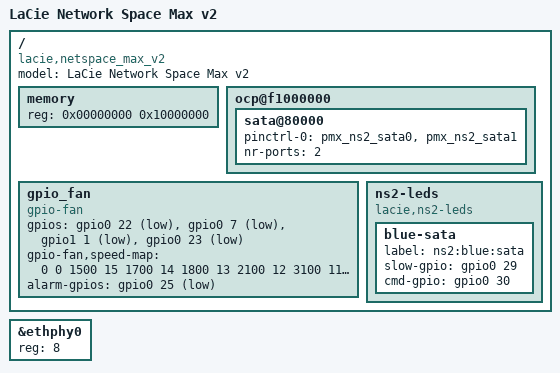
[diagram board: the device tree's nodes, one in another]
/dts-v1/;

#include "kirkwood-ns2-common.dtsi"

/ {
	model = "LaCie Network Space Max v2";
	compatible = "lacie,netspace_max_v2", "marvell,kirkwood-88f6281", "marvell,kirkwood";

	memory {
		device_type = "memory";
		reg = <0x00000000 0x10000000>;
	};

	ocp@f1000000 {
		sata@80000 {
			pinctrl-0 = <&pmx_ns2_sata0 &pmx_ns2_sata1>;
			pinctrl-names = "default";
			status = "okay";
			nr-ports = <2>;
		};
	};

	gpio_fan {
		compatible = "gpio-fan";
		gpios = <&gpio0 22 GPIO_ACTIVE_LOW
			 &gpio0  7 GPIO_ACTIVE_LOW
			 &gpio1  1 GPIO_ACTIVE_LOW
			 &gpio0 23 GPIO_ACTIVE_LOW>;
		gpio-fan,speed-map =
			<   0  0
			 1500 15
			 1700 14
			 1800 13
			 2100 12
			 3100 11
			 3300 10
			 4300  9
			 5500  8>;
		alarm-gpios = <&gpio0 25 GPIO_ACTIVE_LOW>;
	};

	ns2-leds {
		compatible = "lacie,ns2-leds";

		blue-sata {
			label = "ns2:blue:sata";
			slow-gpio = <&gpio0 29 0>;
			cmd-gpio = <&gpio0 30 0>;
		};
	};
};

&ethphy0 { reg = <8>; };
